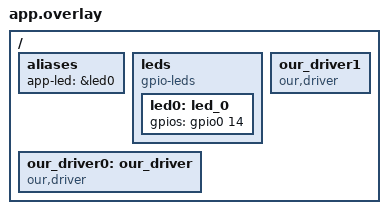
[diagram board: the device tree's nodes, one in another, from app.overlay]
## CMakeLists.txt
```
cmake_minimum_required(VERSION 3.20.0)
set(BOARD esp32s3_devkitc/esp32s3/procpu)

list(APPEND BOARD_ROOT ${CMAKE_CURRENT_SOURCE_DIR})
find_package(Zephyr REQUIRED)
project(app)

target_sources(app PRIVATE src/main.cpp)

add_subdirectory(drivers/our_driver)
```

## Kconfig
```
choice
    prompt "LED blink speed time (ms)"
    default BLINK_SPEED_1000MS

config BLINK_SPEED_250MS
    bool "Fast"

config BLINK_SPEED_500MS
    bool "Medium"

config BLINK_SPEED_1000MS
    bool "Normal"

config BLINK_SPEED_2000MS
    bool "Slow"

endchoice

menuconfig LED_SUBSYSTEM
    bool "LED Subsystem"
    default y
    help
        Enable LED control features

if LED_SUBSYSTEM

config LED_BLINK_SLEEP_TIME_MS
    int
    default 250 if  BLINK_SPEED_250MS
    default 500 if  BLINK_SPEED_500MS
    default 1000 if BLINK_SPEED_1000MS
    default 2000 if BLINK_SPEED_2000MS
    default 0
    help
        Time between LED blinks.

menuconfig ADVANCED_LED_SETTINGS
     bool "Advanced LED Settings"
     default n

config LED_BRIGHTNESS
    int "LED Brightness (0-100)"
    default 100
    range 0 100
    help
        Set the LED brightness level (0-100).

config LED_FADE_DURATION_MS
    int "LED Fade Duration (ms)"
    default 500
    range 0 5000
    help
        Set the duration for LED fade effect in milliseconds.

menu "Expert Settings"
    visible if ADVANCED_LED_SETTINGS

config LED_DEBUG
    bool "Enable LED Debugging"
    default n
    help
        Enable debugging messages for LED operations.

config LED_CUSTOM_PATTERN
    bool "Enable Custom LED Pattern"
    default n
    help
        Allow users to define a custom LED blinking pattern.

endmenu # Expert Settings

endif # LED_SUBSYSTEM

config APP_HEARTBEAT_PERIOD_MS
    int "Heartbeat period (ms)"
    default 500
    range 100 2000

source "Kconfig.zephyr"
rsource "drivers/our_driver/Kconfig"
```

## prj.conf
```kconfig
CONFIG_LOG=y
CONFIG_I2C=y
CONFIG_I2C_SHELL=y
CONFIG_GPIO=y
CONFIG_GPIO_SHELL=y
CONFIG_SENSOR=y
CONFIG_SENSOR_SHELL=y


CONFIG_OUR_DRIVER=y
CONFIG_BLINK_SPEED_2000MS=y

#Shell on the default UART console
CONFIG_SHELL=y

#Enable the Ztest unit testing framework
CONFIG_ZTEST=y

#Randomize suite and test order to catch ordering dependencies early
CONFIG_ZTEST_SAMPLE=y
```

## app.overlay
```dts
/{
	aliases {
		app-led = &led0;
	};
	leds {
		compatible = "gpio-leds";
		led0: led_0 {
			gpios = <&gpio0 14 GPIO_ACTIVE_HIGH>;
		};
	};
	our_driver0: our_driver {
		compatible = "our,driver";
		status = "okay";
	};
	our_driver1: our_driver1 {
		compatible = "our,driver";
		status = "okay";
	};
};
```

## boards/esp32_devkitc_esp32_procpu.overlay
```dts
/ {
	aliases {
		led0 = &led0;
	};

	leds {
		compatible = "gpio-leds";
		led0: led_0 {
			gpios = <&gpio0 2 GPIO_ACTIVE_HIGH>;
		};
	};
};
```

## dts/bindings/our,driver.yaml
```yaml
description: Our Single GPIO driver
compatible: "our,driver"
include: base.yaml
```

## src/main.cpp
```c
#include <zephyr/device.h>
#include <zephyr/logging/log.h>
#include "our_driver.h"

LOG_MODULE_REGISTER(main, LOG_LEVEL_INF);

int main(void)
{
    const struct device *driver = DEVICE_DT_GET(DT_NODELABEL(our_driver0));

    if (!device_is_ready(driver)) {
        LOG_ERR("Sensor driver is not ready");
        return 0;
    }

    int ret = our_driver_set_led_state(driver, false);
    if (ret < 0) {
        LOG_ERR("Failed to set LED state: %d", ret);
    }

    return 0;
}
```
